# STM32H562 register map
File version: 0.1
CPU: CM33 r0p0, little endian, MPU, FPU, 4 interrupt priority bits
Registers are 32-bit, read-write, reset 0x0 unless marked. A register's access mark holds for its fields unless they carry their own. Offsets are from the block's base; [hi:lo] are bit positions.

## USART1 (part 2 of 2) — Universal synchronous asynchronous receiver transmitter
Base 0x40013800
Same registers: USART2 0x40004400, USART3 0x40004800, UART4 0x40004C00, UART5 0x40005000, USART6 0x40006400, USART10 0x40006800, USART11 0x40006C00, UART7 0x40007800, UART8 0x40007C00, UART9 0x40008000, UART12 0x40008400, SEC_USART2 0x50004400, SEC_USART3 0x50004800, SEC_UART4 0x50004C00, SEC_UART5 0x50005000, SEC_USART6 0x50006400, SEC_USART10 0x50006800, SEC_USART11 0x50006C00, SEC_UART7 0x50007800, SEC_UART8 0x50007C00, SEC_UART9 0x50008000, SEC_UART12 0x50008400, SEC_USART1 0x50013800
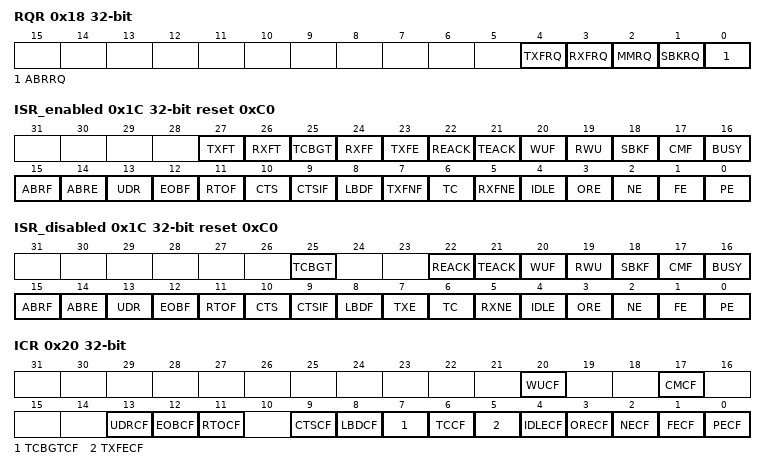
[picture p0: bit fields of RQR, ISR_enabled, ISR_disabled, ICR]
0x18 RQR wo — USART request register
  [4] TXFRQ — Transmit data flush request When FIFO mode is disabled, writing ‘1’ to this bit sets the TXE flag. This enables to discard the transmit data. This bit must be used only in Smartcard mode, when data have not been sent due to errors (NACK) and the FE flag is active in the USART_ISR register. If the USART does not support Smartcard mode, this bit is reserved and must be kept at reset value. When FIFO is enabled, TXFRQ bit is set to flush the whole FIFO. This sets the TXFE flag (Transmit FIFO empty, bit 23 in the USART_ISR register). Flushing the Transmit FIFO is supported in both UART and Smartcard modes. Note: In FIFO mode, the TXFNF flag is reset during the flush request until TxFIFO is empty in order to ensure that no data are written in the data register.
  [3] RXFRQ — Receive data flush request Writing 1 to this bit empties the entire receive FIFO i.e. clears the bit RXFNE. This enables to discard the received data without reading them, and avoid an overrun condition.
  [2] MMRQ — Mute mode request Writing 1 to this bit puts the USART in Mute mode and resets the RWU flag.
  [1] SBKRQ — Send break request Writing 1 to this bit sets the SBKF flag and request to send a BREAK on the line, as soon as the transmit machine is available. Note: When the application needs to send the break character following all previously inserted data, including the ones not yet transmitted, the software should wait for the TXE flag assertion before setting the SBKRQ bit.
  [0] ABRRQ — auto baud rate request Writing 1 to this bit resets the ABRF and ABRE flags in the USART_ISR and requests an automatic baud rate measurement on the next received data frame. Note: If the USART does not support the auto baud rate feature, this bit is reserved and must be kept at reset value. Refer to .
0x1C ISR_enabled ro reset 0xC0 (reset mask 0xF00FFFFF) — USART interrupt and status register
  [27] TXFT — TXFIFO threshold flag This bit is set by hardware when the TXFIFO reaches the threshold programmed in TXFTCFG of USART_CR3 register i.e. the TXFIFO contains TXFTCFG empty locations. An interrupt is generated if the TXFTIE bit =1 (bit 31) in the USART_CR3 register.
  [26] RXFT — RXFIFO threshold flag This bit is set by hardware when the threshold programmed in RXFTCFG in USART_CR3 register is reached. This means that there are (RXFTCFG - 1) data in the Receive FIFO and one data in the USART_RDR register. An interrupt is generated if the RXFTIE bit =1 (bit 27) in the USART_CR3 register. Note: When the RXFTCFG threshold is configured to ‘101’, RXFT flag is set if 16 data are available i.e. 15 data in the RXFIFO and 1 data in the USART_RDR. Consequently, the 17th received data does not cause an overrun error. The overrun error occurs after receiving the 18th data.
  [25] TCBGT — Transmission complete before guard time flag This bit is set when the last data written in the USART_TDR has been transmitted correctly out of the shift register. It is set by hardware in Smartcard mode, if the transmission of a frame containing data is complete and if the smartcard did not send back any NACK. An interrupt is generated if TCBGTIE=1 in the USART_CR3 register. This bit is cleared by software, by writing 1 to the TCBGTCF in the USART_ICR register or by a write to the USART_TDR register. Note: If the USART does not support the Smartcard mode, this bit is reserved and kept at reset value. If the USART supports the Smartcard mode and the Smartcard mode is enabled, the TCBGT reset value is ‘1’. Refer to on page 2297.
  [24] RXFF — RXFIFO Full This bit is set by hardware when the number of received data corresponds to RXFIFO size + 1 (RXFIFO full + 1 data in the USART_RDR register. An interrupt is generated if the RXFFIE bit =1 in the USART_CR1 register.
  [23] TXFE — TXFIFO Empty This bit is set by hardware when TXFIFO is Empty. When the TXFIFO contains at least one data, this flag is cleared. The TXFE flag can also be set by writing 1 to the bit TXFRQ (bit 4) in the USART_RQR register. An interrupt is generated if the TXFEIE bit =1 (bit 30) in the USART_CR1 register.
  [22] REACK — Receive enable acknowledge flag This bit is set/reset by hardware, when the Receive Enable value is taken into account by the USART. It can be used to verify that the USART is ready for reception before entering low-power mode. Note: If the USART does not support the wakeup from Stop feature, this bit is reserved and kept at reset value. Refer to .
  [21] TEACK — Transmit enable acknowledge flag This bit is set/reset by hardware, when the Transmit Enable value is taken into account by the USART. It can be used when an idle frame request is generated by writing TE=0, followed by TE=1 in the USART_CR1 register, in order to respect the TE=0 minimum period.
  [20] WUF — Wakeup from low-power mode flag This bit is set by hardware, when a wakeup event is detected. The event is defined by the WUS bitfield. It is cleared by software, writing a 1 to the WUCF in the USART_ICR register. An interrupt is generated if WUFIE=1 in the USART_CR3 register. Note: When UESM is cleared, WUF flag is also cleared. If the USART does not support the wakeup from Stop feature, this bit is reserved and kept at reset value. Refer to .
  [19] RWU — Receiver wakeup from Mute mode This bit indicates if the USART is in Mute mode. It is cleared/set by hardware when a wakeup/mute sequence is recognized. The Mute mode control sequence (address or IDLE) is selected by the WAKE bit in the USART_CR1 register. When wakeup on IDLE mode is selected, this bit can only be set by software, writing 1 to the MMRQ bit in the USART_RQR register. Note: If the USART does not support the wakeup from Stop feature, this bit is reserved and kept at reset value. Refer to .
  [18] SBKF — Send break flag This bit indicates that a send break character was requested. It is set by software, by writing 1 to the SBKRQ bit in the USART_CR3 register. It is automatically reset by hardware during the stop bit of break transmission.
  [17] CMF — Character match flag This bit is set by hardware, when a the character defined by ADD[7:0] is received. It is cleared by software, writing 1 to the CMCF in the USART_ICR register. An interrupt is generated if CMIE=1in the USART_CR1 register.
  [16] BUSY — Busy flag This bit is set and reset by hardware. It is active when a communication is ongoing on the RX line (successful start bit detected). It is reset at the end of the reception (successful or not).
  [15] ABRF — Auto baud rate flag This bit is set by hardware when the automatic baud rate has been set (RXFNE is also set, generating an interrupt if RXFNEIE = 1) or when the auto baud rate operation was completed without success (ABRE=1) (ABRE, RXFNE and FE are also set in this case) It is cleared by software, in order to request a new auto baud rate detection, by writing 1 to the ABRRQ in the USART_RQR register. Note: If the USART does not support the auto baud rate feature, this bit is reserved and kept at reset value.
  [14] ABRE — Auto baud rate error This bit is set by hardware if the baud rate measurement failed (baud rate out of range or character comparison failed) It is cleared by software, by writing 1 to the ABRRQ bit in the USART_RQR register. Note: If the USART does not support the auto baud rate feature, this bit is reserved and kept at reset value.
  [13] UDR — SPI slave underrun error flag In Slave transmission mode, this flag is set when the first clock pulse for data transmission appears while the software has not yet loaded any value into USART_TDR. This flag is reset by setting UDRCF bit in the USART_ICR register. Note: If the USART does not support the SPI slave mode, this bit is reserved and kept at reset value. Refer to .
  [12] EOBF — End of block flag This bit is set by hardware when a complete block has been received (for example T=1 Smartcard mode). The detection is done when the number of received bytes (from the start of the block, including the prologue) is equal or greater than BLEN + 4. An interrupt is generated if EOBIE = 1 in the USART_CR1 register. It is cleared by software, writing 1 to EOBCF in the USART_ICR register. Note: If Smartcard mode is not supported, this bit is reserved and kept at reset value. Refer to .
  [11] RTOF — Receiver timeout This bit is set by hardware when the timeout value, programmed in the RTOR register has lapsed, without any communication. It is cleared by software, writing 1 to the RTOCF bit in the USART_ICR register. An interrupt is generated if RTOIE=1 in the USART_CR2 register. In Smartcard mode, the timeout corresponds to the CWT or BWT timings. Note: If a time equal to the value programmed in RTOR register separates 2 characters, RTOF is not set. If this time exceeds this value + 2 sample times (2/16 or 2/8, depending on the oversampling method), RTOF flag is set. The counter counts even if RE = 0 but RTOF is set only when RE = 1. If the timeout has already elapsed when RE is set, then RTOF is set. If the USART does not support the Receiver timeout feature, this bit is reserved and kept at reset value.
  [10] CTS — CTS flag This bit is set/reset by hardware. It is an inverted copy of the status of the nCTS input pin. Note: If the hardware flow control feature is not supported, this bit is reserved and kept at reset value.
  [9] CTSIF — CTS interrupt flag This bit is set by hardware when the nCTS input toggles, if the CTSE bit is set. It is cleared by software, by writing 1 to the CTSCF bit in the USART_ICR register. An interrupt is generated if CTSIE=1 in the USART_CR3 register. Note: If the hardware flow control feature is not supported, this bit is reserved and kept at reset value.
  [8] LBDF — LIN break detection flag This bit is set by hardware when the LIN break is detected. It is cleared by software, by writing 1 to the LBDCF in the USART_ICR. An interrupt is generated if LBDIE = 1 in the USART_CR2 register. Note: If the USART does not support LIN mode, this bit is reserved and kept at reset value. Refer to .
  [7] TXFNF — TXFIFO not full TXFNF is set by hardware when TXFIFO is not full meaning that data can be written in the USART_TDR. Every write operation to the USART_TDR places the data in the TXFIFO. This flag remains set until the TXFIFO is full. When the TXFIFO is full, this flag is cleared indicating that data can not be written into the USART_TDR. An interrupt is generated if the TXFNFIE bit =1 in the USART_CR1 register. Note: The TXFNF is kept reset during the flush request until TXFIFO is empty. After sending the flush request (by setting TXFRQ bit), the flag TXFNF should be checked prior to writing in TXFIFO (TXFNF and TXFE is set at the same time). This bit is used during single buffer transmission.
  [6] TC — Transmission complete This bit indicates that the last data written in the USART_TDR has been transmitted out of the shift register. The TC flag behaves as follows: When TDN = 0, the TC flag is set when the transmission of a frame containing data is complete and when TXE/TXFE is set. When TDN is equal to the number of data in the TXFIFO, the TC flag is set when TXFIFO is empty and TDN is reached. When TDN is greater than the number of data in the TXFIFO, TC remains cleared until the TXFIFO is filled again to reach the programmed number of data to be transferred. When TDN is less than the number of data in the TXFIFO, TC is set when TDN is reached even if the TXFIFO is not empty. An interrupt is generated if TCIE=1 in the USART_CR1 register. TC bit is cleared by software by writing 1 to the TCCF in the USART_ICR register or by writing to the USART_TDR register.
  [5] RXFNE — RXFIFO not empty RXFNE bit is set by hardware when the RXFIFO is not empty, meaning that data can be read from the USART_RDR register. Every read operation from the USART_RDR frees a location in the RXFIFO. RXFNE is cleared when the RXFIFO is empty. The RXFNE flag can also be cleared by writing 1 to the RXFRQ in the USART_RQR register. An interrupt is generated if RXFNEIE=1 in the USART_CR1 register.
  [4] IDLE — Idle line detected This bit is set by hardware when an Idle Line is detected. An interrupt is generated if IDLEIE=1 in the USART_CR1 register. It is cleared by software, writing 1 to the IDLECF in the USART_ICR register. Note: The IDLE bit is not set again until the RXFNE bit has been set (i.e. a new idle line occurs). If Mute mode is enabled (MME=1), IDLE is set if the USART is not mute (RWU=0), whatever the Mute mode selected by the WAKE bit. If RWU=1, IDLE is not set.
  [3] ORE — Overrun error This bit is set by hardware when the data currently being received in the shift register is ready to be transferred into the USART_RDR register while RXFF = 1. It is cleared by a software, writing 1 to the ORECF, in the USART_ICR register. An interrupt is generated if RXFNEIE=1 or EIE = 1 in the USART_CR1 register. Note: When this bit is set, the USART_RDR register content is not lost but the shift register is overwritten. An interrupt is generated if the ORE flag is set during multi buffer communication if the EIE bit is set. This bit is permanently forced to 0 (no overrun detection) when the bit OVRDIS is set in the USART_CR3 register.
  [2] NE — Noise detection flag This bit is set by hardware when noise is detected on a received frame. It is cleared by software, writing 1 to the NFCF bit in the USART_ICR register. Note: This bit does not generate an interrupt as it appears at the same time as the RXFNE bit which itself generates an interrupt. An interrupt is generated when the NE flag is set during multi buffer communication if the EIE bit is set. When the line is noise-free, the NE flag can be disabled by programming the ONEBIT bit to 1 to increase the USART tolerance to deviations (Refer to Tolerance of the USART receiver to clock deviation on page 2317). This error is associated with the character in the USART_RDR.
  [1] FE — Framing error This bit is set by hardware when a de-synchronization, excessive noise or a break character is detected. It is cleared by software, writing 1 to the FECF bit in the USART_ICR register. When transmitting data in Smartcard mode, this bit is set when the maximum number of transmit attempts is reached without success (the card NACKs the data frame). An interrupt is generated if EIE = 1 in the USART_CR1 register. Note: This error is associated with the character in the USART_RDR.
  [0] PE — Parity error This bit is set by hardware when a parity error occurs in Reception mode. It is cleared by software, writing 1 to the PECF in the USART_ICR register. An interrupt is generated if PEIE = 1 in the USART_CR1 register. Note: This error is associated with the character in the USART_RDR.
0x1C ISR_disabled ro reset 0xC0 (alternate view of USART_ISR_enabled) — Interrupt and status register
  [25] TCBGT — Transmission complete before guard time flag This bit is set when the last data written in the USART_TDR has been transmitted correctly out of the shift register. It is set by hardware in Smartcard mode, if the transmission of a frame containing data is complete and if the smartcard did not send back any NACK. An interrupt is generated if TCBGTIE=1 in the USART_CR3 register. This bit is cleared by software, by writing 1 to the TCBGTCF in the USART_ICR register or by a write to the USART_TDR register. Note: If the USART does not support the Smartcard mode, this bit is reserved and kept at reset value. If the USART supports the Smartcard mode and the Smartcard mode is enabled, the TCBGT reset value is ‘1’. Refer to on page 2297.
  [22] REACK — Receive enable acknowledge flag This bit is set/reset by hardware, when the Receive Enable value is taken into account by the USART. It can be used to verify that the USART is ready for reception before entering low-power mode. Note: If the USART does not support the wakeup from Stop feature, this bit is reserved and kept at reset value. Refer to .
  [21] TEACK — Transmit enable acknowledge flag This bit is set/reset by hardware, when the Transmit Enable value is taken into account by the USART. It can be used when an idle frame request is generated by writing TE=0, followed by TE=1 in the USART_CR1 register, in order to respect the TE=0 minimum period.
  [20] WUF — Wakeup from low-power mode flag This bit is set by hardware, when a wakeup event is detected. The event is defined by the WUS bitfield. It is cleared by software, writing a 1 to the WUCF in the USART_ICR register. An interrupt is generated if WUFIE=1 in the USART_CR3 register. Note: When UESM is cleared, WUF flag is also cleared. If the USART does not support the wakeup from Stop feature, this bit is reserved and kept at reset value. Refer to .
  [19] RWU — Receiver wakeup from Mute mode This bit indicates if the USART is in Mute mode. It is cleared/set by hardware when a wakeup/mute sequence is recognized. The Mute mode control sequence (address or IDLE) is selected by the WAKE bit in the USART_CR1 register. When wakeup on IDLE mode is selected, this bit can only be set by software, writing 1 to the MMRQ bit in the USART_RQR register. Note: If the USART does not support the wakeup from Stop feature, this bit is reserved and kept at reset value. Refer to .
  [18] SBKF — Send break flag This bit indicates that a send break character was requested. It is set by software, by writing 1 to the SBKRQ bit in the USART_CR3 register. It is automatically reset by hardware during the stop bit of break transmission.
  [17] CMF — Character match flag This bit is set by hardware, when a the character defined by ADD[7:0] is received. It is cleared by software, writing 1 to the CMCF in the USART_ICR register. An interrupt is generated if CMIE=1in the USART_CR1 register.
  [16] BUSY — Busy flag This bit is set and reset by hardware. It is active when a communication is ongoing on the RX line (successful start bit detected). It is reset at the end of the reception (successful or not).
  [15] ABRF — Auto baud rate flag This bit is set by hardware when the automatic baud rate has been set (RXNE is also set, generating an interrupt if RXNEIE = 1) or when the auto baud rate operation was completed without success (ABRE=1) (ABRE, RXNE and FE are also set in this case) It is cleared by software, in order to request a new auto baud rate detection, by writing 1 to the ABRRQ in the USART_RQR register. Note: If the USART does not support the auto baud rate feature, this bit is reserved and kept at reset value.
  [14] ABRE — Auto baud rate error This bit is set by hardware if the baud rate measurement failed (baud rate out of range or character comparison failed) It is cleared by software, by writing 1 to the ABRRQ bit in the USART_RQR register. Note: If the USART does not support the auto baud rate feature, this bit is reserved and kept at reset value.
  [13] UDR — SPI slave underrun error flag In Slave transmission mode, this flag is set when the first clock pulse for data transmission appears while the software has not yet loaded any value into USART_TDR. This flag is reset by setting UDRCF bit in the USART_ICR register. Note: If the USART does not support the SPI slave mode, this bit is reserved and kept at reset value. Refer to .
  [12] EOBF — End of block flag This bit is set by hardware when a complete block has been received (for example T=1 Smartcard mode). The detection is done when the number of received bytes (from the start of the block, including the prologue) is equal or greater than BLEN + 4. An interrupt is generated if EOBIE = 1 in the USART_CR1 register. It is cleared by software, writing 1 to EOBCF in the USART_ICR register. Note: If Smartcard mode is not supported, this bit is reserved and kept at reset value. Refer to .
  [11] RTOF — Receiver timeout This bit is set by hardware when the timeout value, programmed in the RTOR register has lapsed, without any communication. It is cleared by software, writing 1 to the RTOCF bit in the USART_ICR register. An interrupt is generated if RTOIE=1 in the USART_CR2 register. In Smartcard mode, the timeout corresponds to the CWT or BWT timings. Note: If a time equal to the value programmed in RTOR register separates 2 characters, RTOF is not set. If this time exceeds this value + 2 sample times (2/16 or 2/8, depending on the oversampling method), RTOF flag is set. The counter counts even if RE = 0 but RTOF is set only when RE = 1. If the timeout has already elapsed when RE is set, then RTOF is set. If the USART does not support the Receiver timeout feature, this bit is reserved and kept at reset value.
  [10] CTS — CTS flag This bit is set/reset by hardware. It is an inverted copy of the status of the nCTS input pin. Note: If the hardware flow control feature is not supported, this bit is reserved and kept at reset value.
  [9] CTSIF — CTS interrupt flag This bit is set by hardware when the nCTS input toggles, if the CTSE bit is set. It is cleared by software, by writing 1 to the CTSCF bit in the USART_ICR register. An interrupt is generated if CTSIE=1 in the USART_CR3 register. Note: If the hardware flow control feature is not supported, this bit is reserved and kept at reset value.
  [8] LBDF — LIN break detection flag This bit is set by hardware when the LIN break is detected. It is cleared by software, by writing 1 to the LBDCF in the USART_ICR. An interrupt is generated if LBDIE = 1 in the USART_CR2 register. Note: If the USART does not support LIN mode, this bit is reserved and kept at reset value. Refer to .
  [7] TXE — Transmit data register empty TXE is set by hardware when the content of the USART_TDR register has been transferred into the shift register. It is cleared by writing to the USART_TDR register. The TXE flag can also be set by writing 1 to the TXFRQ in the USART_RQR register, in order to discard the data (only in Smartcard T=0 mode, in case of transmission failure). An interrupt is generated if the TXEIE bit =1 in the USART_CR1 register.
  [6] TC — Transmission complete This bit indicates that the last data written in the USART_TDR has been transmitted out of the shift register. The TC flag is set when the transmission of a frame containing data is complete and when TXE is set. An interrupt is generated if TCIE=1 in the USART_CR1 register. TC bit is cleared by software by writing 1 to the TCCF in the USART_ICR register or by writing to the USART_TDR register.
  [5] RXNE — Read data register not empty RXNE bit is set by hardware when the content of the USART_RDR shift register has been transferred to the USART_RDR register. It is cleared by reading from the USART_RDR register. The RXNE flag can also be cleared by writing 1 to the RXFRQ in the USART_RQR register. An interrupt is generated if RXNEIE=1 in the USART_CR1 register.
  [4] IDLE — Idle line detected This bit is set by hardware when an Idle Line is detected. An interrupt is generated if IDLEIE=1 in the USART_CR1 register. It is cleared by software, writing 1 to the IDLECF in the USART_ICR register. Note: The IDLE bit is not set again until the RXNE bit has been set (i.e. a new idle line occurs). If Mute mode is enabled (MME=1), IDLE is set if the USART is not mute (RWU=0), whatever the Mute mode selected by the WAKE bit. If RWU=1, IDLE is not set.
  [3] ORE — Overrun error This bit is set by hardware when the data currently being received in the shift register is ready to be transferred into the USART_RDR register while RXNE=1. It is cleared by a software, writing 1 to the ORECF, in the USART_ICR register. An interrupt is generated if RXNEIE=1 or EIE = 1 in the USART_CR1 register. Note: When this bit is set, the USART_RDR register content is not lost but the shift register is overwritten. An interrupt is generated if the ORE flag is set during multi buffer communication if the EIE bit is set. This bit is permanently forced to 0 (no overrun detection) when the bit OVRDIS is set in the USART_CR3 register.
  [2] NE — Noise detection flag This bit is set by hardware when noise is detected on a received frame. It is cleared by software, writing 1 to the NFCF bit in the USART_ICR register. Note: This bit does not generate an interrupt as it appears at the same time as the RXNE bit which itself generates an interrupt. An interrupt is generated when the NE flag is set during multi buffer communication if the EIE bit is set. When the line is noise-free, the NE flag can be disabled by programming the ONEBIT bit to 1 to increase the USART tolerance to deviations (Refer to Tolerance of the USART receiver to clock deviation on page 2317). This error is associated with the character in the USART_RDR.
  [1] FE — Framing error This bit is set by hardware when a de-synchronization, excessive noise or a break character is detected. It is cleared by software, writing 1 to the FECF bit in the USART_ICR register. When transmitting data in Smartcard mode, this bit is set when the maximum number of transmit attempts is reached without success (the card NACKs the data frame). An interrupt is generated if EIE = 1 in the USART_CR1 register. Note: This error is associated with the character in the USART_RDR.
  [0] PE — Parity error This bit is set by hardware when a parity error occurs in Reception mode. It is cleared by software, writing 1 to the PECF in the USART_ICR register. An interrupt is generated if PEIE = 1 in the USART_CR1 register. Note: This error is associated with the character in the USART_RDR.
0x20 ICR wo — USART interrupt flag clear register
  [20] WUCF — Wakeup from low-power mode clear flag Writing 1 to this bit clears the WUF flag in the USART_ISR register. Note: If the USART does not support the wakeup from Stop feature, this bit is reserved and must be kept at reset value. Refer to page 2297.
  [17] CMCF — Character match clear flag Writing 1 to this bit clears the CMF flag in the USART_ISR register.
  [13] UDRCF — SPI slave underrun clear flag Writing 1 to this bit clears the UDRF flag in the USART_ISR register. Note: If the USART does not support SPI slave mode, this bit is reserved and must be kept at reset value. Refer to
  [12] EOBCF — End of block clear flag Writing 1 to this bit clears the EOBF flag in the USART_ISR register. Note: If the USART does not support Smartcard mode, this bit is reserved and must be kept at reset value. Refer to .
  [11] RTOCF — Receiver timeout clear flag Writing 1 to this bit clears the RTOF flag in the USART_ISR register. Note: If the USART does not support the Receiver timeout feature, this bit is reserved and must be kept at reset value. Refer to page 2297.
  [9] CTSCF — CTS clear flag Writing 1 to this bit clears the CTSIF flag in the USART_ISR register. Note: If the hardware flow control feature is not supported, this bit is reserved and must be kept at reset value. Refer to .
  [8] LBDCF — LIN break detection clear flag Writing 1 to this bit clears the LBDF flag in the USART_ISR register. Note: If LIN mode is not supported, this bit is reserved and must be kept at reset value. Refer to .
  [7] TCBGTCF — Transmission complete before Guard time clear flag Writing 1 to this bit clears the TCBGT flag in the USART_ISR register.
  [6] TCCF — Transmission complete clear flag Writing 1 to this bit clears the TC flag in the USART_ISR register.
  [5] TXFECF — TXFIFO empty clear flag Writing 1 to this bit clears the TXFE flag in the USART_ISR register.
  [4] IDLECF — Idle line detected clear flag Writing 1 to this bit clears the IDLE flag in the USART_ISR register.
  [3] ORECF — Overrun error clear flag Writing 1 to this bit clears the ORE flag in the USART_ISR register.
  [2] NECF — Noise detected clear flag Writing 1 to this bit clears the NE flag in the USART_ISR register.
  [1] FECF — Framing error clear flag Writing 1 to this bit clears the FE flag in the USART_ISR register.
  [0] PECF — Parity error clear flag Writing 1 to this bit clears the PE flag in the USART_ISR register.
0x24 RDR ro — USART receive data register
  [8:0] RDR — Receive data value Contains the received data character. The RDR register provides the parallel interface between the input shift register and the internal bus (see ). When receiving with the parity enabled, the value read in the MSB bit is the received parity bit.
0x28 TDR — USART transmit data register
  [8:0] TDR — Transmit data value Contains the data character to be transmitted. The USART_TDR register provides the parallel interface between the internal bus and the output shift register (see ). When transmitting with the parity enabled (PCE bit set to 1 in the USART_CR1 register), the value written in the MSB (bit 7 or bit 8 depending on the data length) has no effect because it is replaced by the parity. Note: This register must be written only when TXE/TXFNF=1.
0x2C PRESC — USART prescaler register
  [3:0] PRESCALER — Clock prescaler The USART input clock can be divided by a prescaler factor: Remaining combinations: Reserved Note: When PRESCALER is programmed with a value different of the allowed ones, programmed prescaler value is equal to ‘1011’ i.e. input clock divided by 256.
